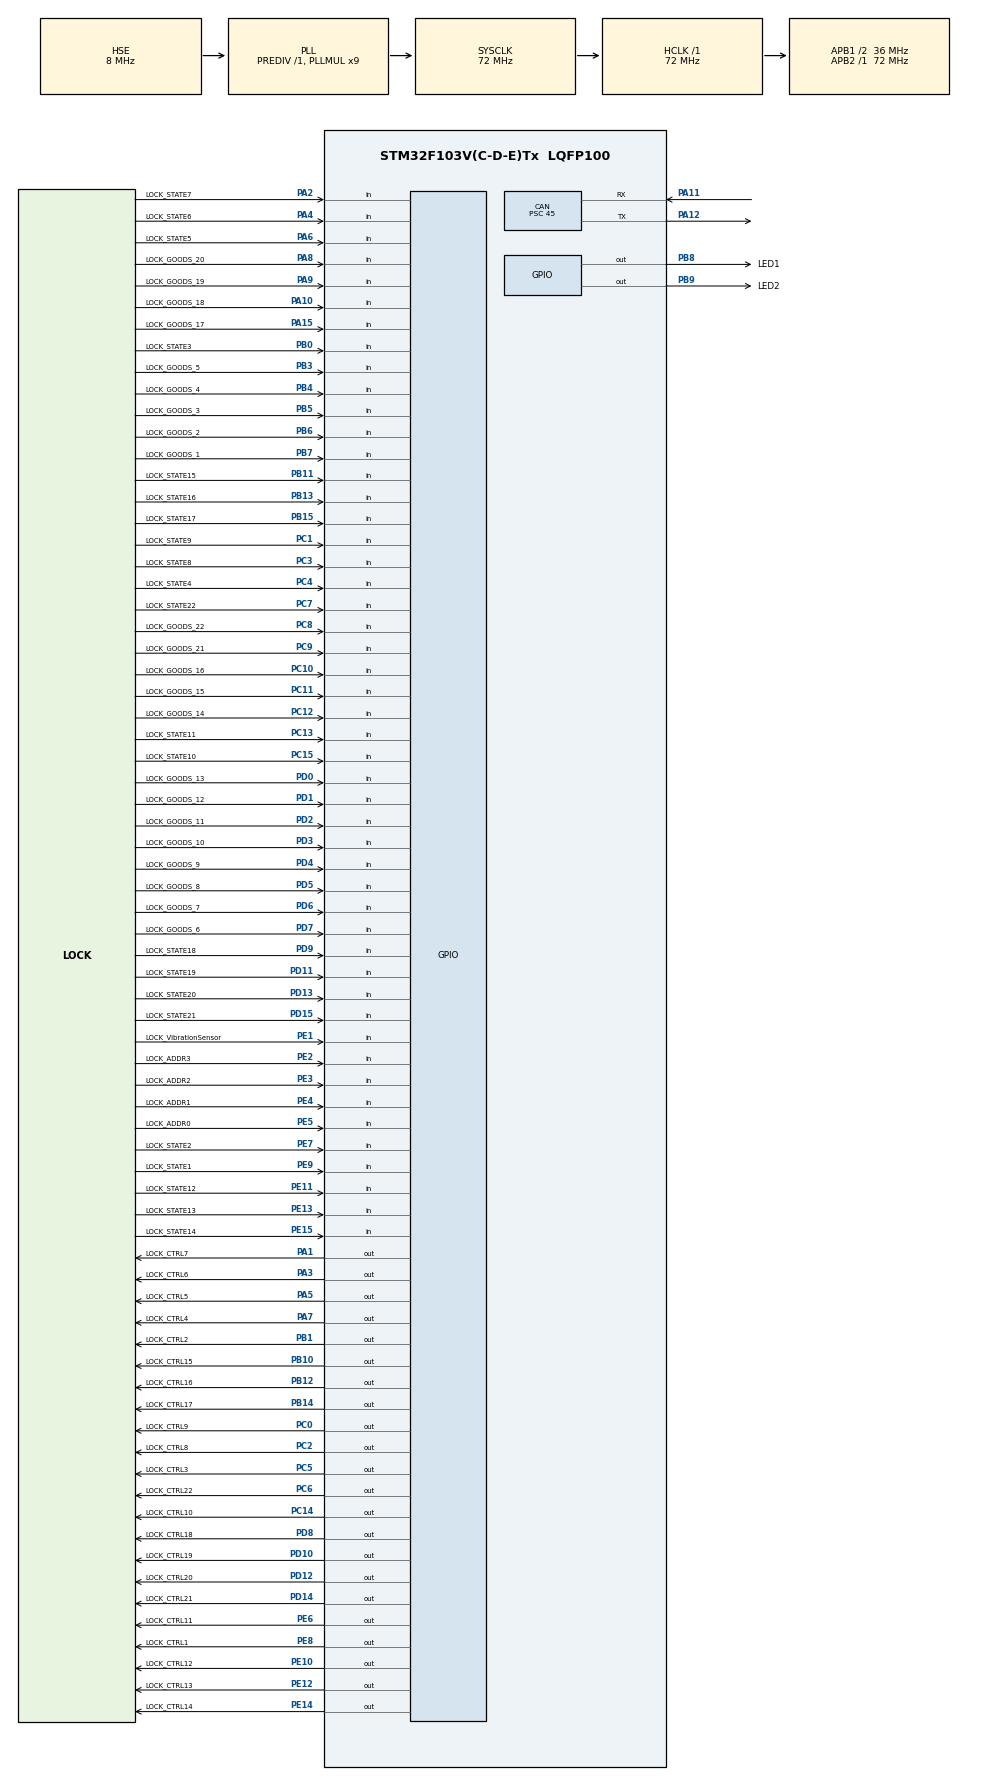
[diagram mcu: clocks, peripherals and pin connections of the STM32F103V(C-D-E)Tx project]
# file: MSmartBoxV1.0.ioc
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CAN.ABOM=ENABLE
CAN.BS1=CAN_BS1_4TQ
CAN.BS2=CAN_BS2_3TQ
CAN.CalculateTimeBit=10000
CAN.CalculateTimeQuantum=1250.0
CAN.Prescaler=45
Mcu.Family=STM32F1
Mcu.Name=STM32F103V(C-D-E)Tx
Mcu.Package=LQFP100
NVIC.CAN1_RX1_IRQn=true\:0\:0\:false\:true\:true\:2\:true
NVIC.CAN1_SCE_IRQn=true\:0\:0\:false\:true\:true\:3\:true
NVIC.PriorityGroup=NVIC_PRIORITYGROUP_4
NVIC.TIM4_IRQn=true\:0\:0\:false\:true\:true\:4\:true
NVIC.TIM5_IRQn=true\:0\:0\:false\:true\:true\:5\:true
NVIC.USB_LP_CAN1_RX0_IRQn=true\:0\:0\:false\:true\:true\:1\:true
OSC_IN.Mode=HSE-External-Oscillator
OSC_IN.Signal=RCC_OSC_IN
OSC_OUT.Mode=HSE-External-Oscillator
OSC_OUT.Signal=RCC_OSC_OUT
PA1.GPIO_Label=LOCK_CTRL7
PA1.PinState=GPIO_PIN_SET
PA1.Signal=GPIO_Output
PA10.GPIO_Label=LOCK_GOODS_18
PA10.Signal=GPIO_Input
PA11.Mode=Master
PA11.Signal=CAN_RX
PA12.Mode=Master
PA12.Signal=CAN_TX
PA13.Mode=Serial_Wire
PA13.Signal=SYS_JTMS-SWDIO
PA14.Mode=Serial_Wire
PA14.Signal=SYS_JTCK-SWCLK
PA15.GPIO_Label=LOCK_GOODS_17
PA15.Signal=GPIO_Input
PA2.GPIO_Label=LOCK_STATE7
PA2.Signal=GPIO_Input
PA3.GPIO_Label=LOCK_CTRL6
PA3.PinState=GPIO_PIN_SET
PA3.Signal=GPIO_Output
PA4.GPIO_Label=LOCK_STATE6
PA4.Signal=GPIO_Input
PA5.GPIO_Label=LOCK_CTRL5
PA5.Signal=GPIO_Output
PA6.GPIO_Label=LOCK_STATE5
PA6.Signal=GPIO_Input
PA7.GPIO_Label=LOCK_CTRL4
PA7.PinState=GPIO_PIN_SET
PA7.Signal=GPIO_Output
PA8.GPIO_Label=LOCK_GOODS_20
PA8.Signal=GPIO_Input
PA9.GPIO_Label=LOCK_GOODS_19
PA9.Signal=GPIO_Input
PB0.GPIO_Label=LOCK_STATE3
PB0.Signal=GPIO_Input
PB1.GPIO_Label=LOCK_CTRL2
PB1.PinState=GPIO_PIN_SET
PB1.Signal=GPIO_Output
PB10.GPIO_Label=LOCK_CTRL15
PB10.PinState=GPIO_PIN_SET
PB10.Signal=GPIO_Output
PB11.GPIO_Label=LOCK_STATE15
PB11.Signal=GPIO_Input
PB12.GPIO_Label=LOCK_CTRL16
PB12.PinState=GPIO_PIN_SET
PB12.Signal=GPIO_Output
PB13.GPIO_Label=LOCK_STATE16
PB13.Signal=GPIO_Input
PB14.GPIO_Label=LOCK_CTRL17
PB14.PinState=GPIO_PIN_SET
PB14.Signal=GPIO_Output
PB15.GPIO_Label=LOCK_STATE17
PB15.Signal=GPIO_Input
PB3.GPIO_Label=LOCK_GOODS_5
PB3.Signal=GPIO_Input
PB4.GPIO_Label=LOCK_GOODS_4
PB4.Signal=GPIO_Input
PB5.GPIO_Label=LOCK_GOODS_3
PB5.Signal=GPIO_Input
PB6.GPIO_Label=LOCK_GOODS_2
PB6.Signal=GPIO_Input
PB7.GPIO_Label=LOCK_GOODS_1
PB7.Signal=GPIO_Input
PB8.GPIO_Label=LED1
PB8.PinState=GPIO_PIN_SET
PB8.Signal=GPIO_Output
PB9.GPIO_Label=LED2
PB9.PinState=GPIO_PIN_SET
PB9.Signal=GPIO_Output
PC0.GPIO_Label=LOCK_CTRL9
PC0.PinState=GPIO_PIN_SET
PC0.Signal=GPIO_Output
PC1.GPIO_Label=LOCK_STATE9
PC1.Signal=GPIO_Input
PC10.GPIO_Label=LOCK_GOODS_16
PC10.Signal=GPIO_Input
PC11.GPIO_Label=LOCK_GOODS_15
PC11.Signal=GPIO_Input
PC12.GPIO_Label=LOCK_GOODS_14
PC12.Signal=GPIO_Input
PC13-TAMPER-RTC.GPIO_Label=LOCK_STATE11
PC13-TAMPER-RTC.Signal=GPIO_Input
PC14-OSC32_IN.GPIO_Label=LOCK_CTRL10
PC14-OSC32_IN.PinState=GPIO_PIN_SET
PC14-OSC32_IN.Signal=GPIO_Output
PC15-OSC32_OUT.GPIO_Label=LOCK_STATE10
PC15-OSC32_OUT.Signal=GPIO_Input
PC2.GPIO_Label=LOCK_CTRL8
PC2.PinState=GPIO_PIN_SET
PC2.Signal=GPIO_Output
PC3.GPIO_Label=LOCK_STATE8
PC3.Signal=GPIO_Input
PC4.GPIO_Label=LOCK_STATE4
PC4.Signal=GPIO_Input
PC5.GPIO_Label=LOCK_CTRL3
PC5.PinState=GPIO_PIN_SET
PC5.Signal=GPIO_Output
PC6.GPIO_Label=LOCK_CTRL22
PC6.PinState=GPIO_PIN_SET
PC6.Signal=GPIO_Output
PC7.GPIO_Label=LOCK_STATE22
PC7.Signal=GPIO_Input
PC8.GPIO_Label=LOCK_GOODS_22
PC8.Signal=GPIO_Input
PC9.GPIO_Label=LOCK_GOODS_21
PC9.Signal=GPIO_Input
PD0.GPIO_Label=LOCK_GOODS_13
PD0.Signal=GPIO_Input
PD1.GPIO_Label=LOCK_GOODS_12
PD1.Signal=GPIO_Input
PD10.GPIO_Label=LOCK_CTRL19
PD10.PinState=GPIO_PIN_SET
PD10.Signal=GPIO_Output
PD11.GPIO_Label=LOCK_STATE19
PD11.Signal=GPIO_Input
PD12.GPIO_Label=LOCK_CTRL20
PD12.PinState=GPIO_PIN_SET
PD12.Signal=GPIO_Output
PD13.GPIO_Label=LOCK_STATE20
PD13.Signal=GPIO_Input
PD14.GPIO_Label=LOCK_CTRL21
PD14.PinState=GPIO_PIN_SET
PD14.Signal=GPIO_Output
PD15.GPIO_Label=LOCK_STATE21
PD15.Signal=GPIO_Input
PD2.GPIO_Label=LOCK_GOODS_11
PD2.Signal=GPIO_Input
PD3.GPIO_Label=LOCK_GOODS_10
PD3.Signal=GPIO_Input
PD4.GPIO_Label=LOCK_GOODS_9
PD4.Signal=GPIO_Input
PD5.GPIO_Label=LOCK_GOODS_8
PD5.Signal=GPIO_Input
PD6.GPIO_Label=LOCK_GOODS_7
PD6.Signal=GPIO_Input
PD7.GPIO_Label=LOCK_GOODS_6
PD7.Signal=GPIO_Input
PD8.GPIO_Label=LOCK_CTRL18
PD8.PinState=GPIO_PIN_SET
PD8.Signal=GPIO_Output
PD9.GPIO_Label=LOCK_STATE18
PD9.Signal=GPIO_Input
PE1.GPIO_Label=LOCK_VibrationSensor
PE1.Signal=GPIO_Input
PE10.GPIO_Label=LOCK_CTRL12
PE10.PinState=GPIO_PIN_SET
PE10.Signal=GPIO_Output
PE11.GPIO_Label=LOCK_STATE12
PE11.Signal=GPIO_Input
PE12.GPIO_Label=LOCK_CTRL13
PE12.PinState=GPIO_PIN_SET
PE12.Signal=GPIO_Output
PE13.GPIO_Label=LOCK_STATE13
PE13.Signal=GPIO_Input
PE14.GPIO_Label=LOCK_CTRL14
PE14.PinState=GPIO_PIN_SET
PE14.Signal=GPIO_Output
PE15.GPIO_Label=LOCK_STATE14
PE15.Signal=GPIO_Input
PE2.GPIO_Label=LOCK_ADDR3
PE2.Signal=GPIO_Input
PE3.GPIO_Label=LOCK_ADDR2
PE3.Signal=GPIO_Input
PE4.GPIO_Label=LOCK_ADDR1
PE4.Signal=GPIO_Input
PE5.GPIO_Label=LOCK_ADDR0
PE5.Signal=GPIO_Input
PE6.GPIO_Label=LOCK_CTRL11
PE6.PinState=GPIO_PIN_SET
PE6.Signal=GPIO_Output
PE7.GPIO_Label=LOCK_STATE2
PE7.Signal=GPIO_Input
PE8.GPIO_Label=LOCK_CTRL1
PE8.PinState=GPIO_PIN_SET
PE8.Signal=GPIO_Output
PE9.GPIO_Label=LOCK_STATE1
PE9.Signal=GPIO_Input
ProjectManager.HeapSize=0x200
ProjectManager.StackSize=0x400
ProjectManager.TargetToolchain=EWARM
RCC.AHBFreq_Value=72000000
RCC.APB1CLKDivider=RCC_HCLK_DIV2
RCC.APB1Freq_Value=36000000
RCC.APB1TimFreq_Value=72000000
RCC.APB2Freq_Value=72000000
RCC.APB2TimFreq_Value=72000000
RCC.HCLKFreq_Value=72000000
RCC.PLLMUL=RCC_PLL_MUL9
RCC.PLLSourceVirtual=RCC_PLLSOURCE_HSE
RCC.SYSCLKFreq_VALUE=72000000
RCC.SYSCLKSource=RCC_SYSCLKSOURCE_PLLCLK
RCC.USBFreq_Value=72000000
TIM4.Period=1000-1
TIM4.Prescaler=72-1
TIM5.Period=2000-1
TIM5.Prescaler=3600-1
VP_TIM4_VS_ClockSourceINT.Mode=Internal
VP_TIM5_VS_ClockSourceINT.Mode=Internal
board=MSmartBoxV1.0

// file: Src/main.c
/**
  ******************************************************************************
  * @file           : main.c
  * @brief          : Main program body
  ******************************************************************************
  ** This notice applies to any and all portions of this file
  * that are not between comment pairs USER CODE BEGIN and
  * USER CODE END. Other portions of this file, whether
  * inserted by the user or by software development tools
  * are owned by their respective copyright owners.
  *
  * COPYRIGHT(c) 2018 STMicroelectronics
  *
  * Redistribution and use in source and binary forms, with or without modification,
  * are permitted provided that the following conditions are met:
  *   1. Redistributions of source code must retain the above copyright notice,
  *      this list of conditions and the following disclaimer.
  *   2. Redistributions in binary form must reproduce the above copyright notice,
  *      this list of conditions and the following disclaimer in the documentation
  *      and/or other materials provided with the distribution.
  *   3. Neither the name of STMicroelectronics nor the names of its contributors
  *      may be used to endorse or promote products derived from this software
  *      without specific prior written permission.
  *
  * THIS SOFTWARE IS PROVIDED BY THE COPYRIGHT HOLDERS AND CONTRIBUTORS "AS IS"
  * AND ANY EXPRESS OR IMPLIED WARRANTIES, INCLUDING, BUT NOT LIMITED TO, THE
  * IMPLIED WARRANTIES OF MERCHANTABILITY AND FITNESS FOR A PARTICULAR PURPOSE ARE
  * DISCLAIMED. IN NO EVENT SHALL THE COPYRIGHT HOLDER OR CONTRIBUTORS BE LIABLE
  * FOR ANY DIRECT, INDIRECT, INCIDENTAL, SPECIAL, EXEMPLARY, OR CONSEQUENTIAL
  * DAMAGES (INCLUDING, BUT NOT LIMITED TO, PROCUREMENT OF SUBSTITUTE GOODS OR
  * SERVICES; LOSS OF USE, DATA, OR PROFITS; OR BUSINESS INTERRUPTION) HOWEVER
  * CAUSED AND ON ANY THEORY OF LIABILITY, WHETHER IN CONTRACT, STRICT LIABILITY,
  * OR TORT (INCLUDING NEGLIGENCE OR OTHERWISE) ARISING IN ANY WAY OUT OF THE USE
  * OF THIS SOFTWARE, EVEN IF ADVISED OF THE POSSIBILITY OF SUCH DAMAGE.
  *
  ******************************************************************************
  */
#include "main.h"
#include "stm32f1xx_hal.h"
#include "can.h"
#include "tim.h"
#include "gpio.h"

/* USER CODE BEGIN Includes */
#include "bsp_Can.h"
#include "bsp_LockGpio.h"
/* USER CODE END Includes */

/* USER CODE BEGIN PV */
/* Private variables ---------------------------------------------------------*/
extern uint8_t CanId;
uint16_t Tim4Cnt;
uint8_t  Tim4CntFlag;
uint8_t checkFlag;
uint16_t Tim5Cnt;
uint8_t  Tim5CntFlag;

/* USER CODE END PV */

void SystemClock_Config(void);
static void MX_NVIC_Init(void);

/* USER CODE BEGIN PFP */
/* Private function prototypes -----------------------------------------------*/

/* USER CODE END PFP */

int main(void)
{

  /* MCU Configuration----------------------------------------------------------*/

  /* Reset of all peripherals, Initializes the Flash interface and the Systick. */
  HAL_Init();

  /* Configure the system clock */
  SystemClock_Config();

  /* Initialize all configured peripherals */
  MX_GPIO_Init();
  MX_CAN_Init();
  MX_TIM4_Init();
  MX_TIM5_Init();

  /* Initialize interrupts */
  MX_NVIC_Init();
  /* USER CODE BEGIN 2 */
  BSP_CanInit();
  BSP_CanFilterConfig();
  HAL_CAN_Receive_IT(&hcan, CAN_FIFO0);
  HAL_TIM_Base_Start_IT(&htim4);
  HAL_TIM_Base_Start_IT(&htim5);
  BSP_LOCKInit();

  /* USER CODE END 2 */

  /* Infinite loop */
  while (1)
  {

  /* USER CODE BEGIN 3 */

  	if(Tim4CntFlag)
  	{
		Tim4CntFlag = 0;
		BSP_LOCKUpdateOfGoodsState();
		BSP_LOCKSendGoodsChangedMessage();

		BSP_LOCKUpdateOfLockPinsState();
		BSP_LOCKSendPinsChangedMessage();
	}

	BSP_LOCKCheckCtrlBuffer();
/*
	if(Tim5CntFlag)
	{
		Tim5CntFlag = 0;
		BSP_CanSendDatas(CanId,0x01,0x02,0x03);
	}
 */
//    BSP_LOCKWriteCtrlPin(0,(CtrlState)0);
//    HAL_Delay(500);

  }
  /* USER CODE END 3 */

}

void SystemClock_Config(void)
{

  RCC_OscInitTypeDef RCC_OscInitStruct;
  RCC_ClkInitTypeDef RCC_ClkInitStruct;

    /**Initializes the CPU, AHB and APB busses clocks
    */
  RCC_OscInitStruct.OscillatorType = RCC_OSCILLATORTYPE_HSE;
  RCC_OscInitStruct.HSEState = RCC_HSE_ON;
  RCC_OscInitStruct.HSEPredivValue = RCC_HSE_PREDIV_DIV1;
  RCC_OscInitStruct.HSIState = RCC_HSI_ON;
  RCC_OscInitStruct.PLL.PLLState = RCC_PLL_ON;
  RCC_OscInitStruct.PLL.PLLSource = RCC_PLLSOURCE_HSE;
  RCC_OscInitStruct.PLL.PLLMUL = RCC_PLL_MUL9;
  if (HAL_RCC_OscConfig(&RCC_OscInitStruct) != HAL_OK)
  {
    _Error_Handler(__FILE__, __LINE__);
  }

    /**Initializes the CPU, AHB and APB busses clocks
    */
  RCC_ClkInitStruct.ClockType = RCC_CLOCKTYPE_HCLK|RCC_CLOCKTYPE_SYSCLK
                              |RCC_CLOCKTYPE_PCLK1|RCC_CLOCKTYPE_PCLK2;
  RCC_ClkInitStruct.SYSCLKSource = RCC_SYSCLKSOURCE_PLLCLK;
  RCC_ClkInitStruct.AHBCLKDivider = RCC_SYSCLK_DIV1;
  RCC_ClkInitStruct.APB1CLKDivider = RCC_HCLK_DIV2;
  RCC_ClkInitStruct.APB2CLKDivider = RCC_HCLK_DIV1;

  if (HAL_RCC_ClockConfig(&RCC_ClkInitStruct, FLASH_LATENCY_2) != HAL_OK)
  {
    _Error_Handler(__FILE__, __LINE__);
  }

    /**Configure the Systick interrupt time
    */
  HAL_SYSTICK_Config(HAL_RCC_GetHCLKFreq()/1000);

    /**Configure the Systick
    */
  HAL_SYSTICK_CLKSourceConfig(SYSTICK_CLKSOURCE_HCLK);

  /* SysTick_IRQn interrupt configuration */
  HAL_NVIC_SetPriority(SysTick_IRQn, 0, 0);
}

/**
  * @brief NVIC Configuration.
  * @retval None
  */
static void MX_NVIC_Init(void)
{
  /* USB_LP_CAN1_RX0_IRQn interrupt configuration */
  HAL_NVIC_SetPriority(USB_LP_CAN1_RX0_IRQn, 0, 0);
  HAL_NVIC_EnableIRQ(USB_LP_CAN1_RX0_IRQn);
  /* CAN1_RX1_IRQn interrupt configuration */
  HAL_NVIC_SetPriority(CAN1_RX1_IRQn, 0, 0);
  HAL_NVIC_EnableIRQ(CAN1_RX1_IRQn);
  /* CAN1_SCE_IRQn interrupt configuration */
  HAL_NVIC_SetPriority(CAN1_SCE_IRQn, 0, 0);
  HAL_NVIC_EnableIRQ(CAN1_SCE_IRQn);
  /* TIM4_IRQn interrupt configuration */
  HAL_NVIC_SetPriority(TIM4_IRQn, 0, 0);
  HAL_NVIC_EnableIRQ(TIM4_IRQn);
  /* TIM5_IRQn interrupt configuration */
  HAL_NVIC_SetPriority(TIM5_IRQn, 0, 0);
  HAL_NVIC_EnableIRQ(TIM5_IRQn);
}

/* USER CODE BEGIN 4 */
/**
  * @brief  Transmission  complete callback in non blocking mode
  * @param  hcan: pointer to a CAN_HandleTypeDef structure that contains
  *         the configuration information for the specified CAN.
  * @retval None
  */
void HAL_CAN_RxCpltCallback(CAN_HandleTypeDef* hcan)
{
  /* Prevent unused argument(s) compilation warning */
  UNUSED(hcan);
  /* NOTE : This function Should not be modified, when the callback is needed,
            the HAL_CAN_RxCpltCallback can be implemented in the user file
   */
	if(CanId == (hcan->pRxMsg->StdId))
	{

		BSP_LOCKWriteCtrlBuffer(hcan->pRxMsg->Data[0]);
		//BSP_CanSendDatas(hcan->pRxMsg->StdId, hcan->pRxMsg->Data[0], hcan->pRxMsg->Data[1], hcan->pRxMsg->Data[2]);
		HAL_GPIO_TogglePin(LED2_GPIO_Port, LED2_Pin);
		HAL_CAN_Receive_IT(hcan, CAN_FIFO0);
	}
}
/**
  * @brief  Period elapsed callback in non blocking mode
  * @param  htim : TIM handle
  * @retval None
  */
void HAL_TIM_PeriodElapsedCallback(TIM_HandleTypeDef *htim)
{
  /* Prevent unused argument(s) compilation warning */
  UNUSED(htim);
  /* NOTE : This function Should not be modified, when the callback is needed,
            the __HAL_TIM_PeriodElapsedCallback could be implemented in the user file
   */
   if(htim4.Instance == htim->Instance)
   {
		Tim4Cnt++;
		if(Tim4Cnt > 49)
		{
			Tim4Cnt = 0;
			Tim4CntFlag = 1;
		}
   }

   if(htim5.Instance == htim->Instance)
   {
		Tim5Cnt ++;
		if(Tim5Cnt > 5000)
		{
			Tim5Cnt = 0;
			Tim5CntFlag = 1;
		}
   }

}

/* USER CODE END 4 */

void _Error_Handler(char *file, int line)
{
  while(1)
  {
  }
}

/************************ (C) COPYRIGHT STMicroelectronics *****END OF FILE****/
